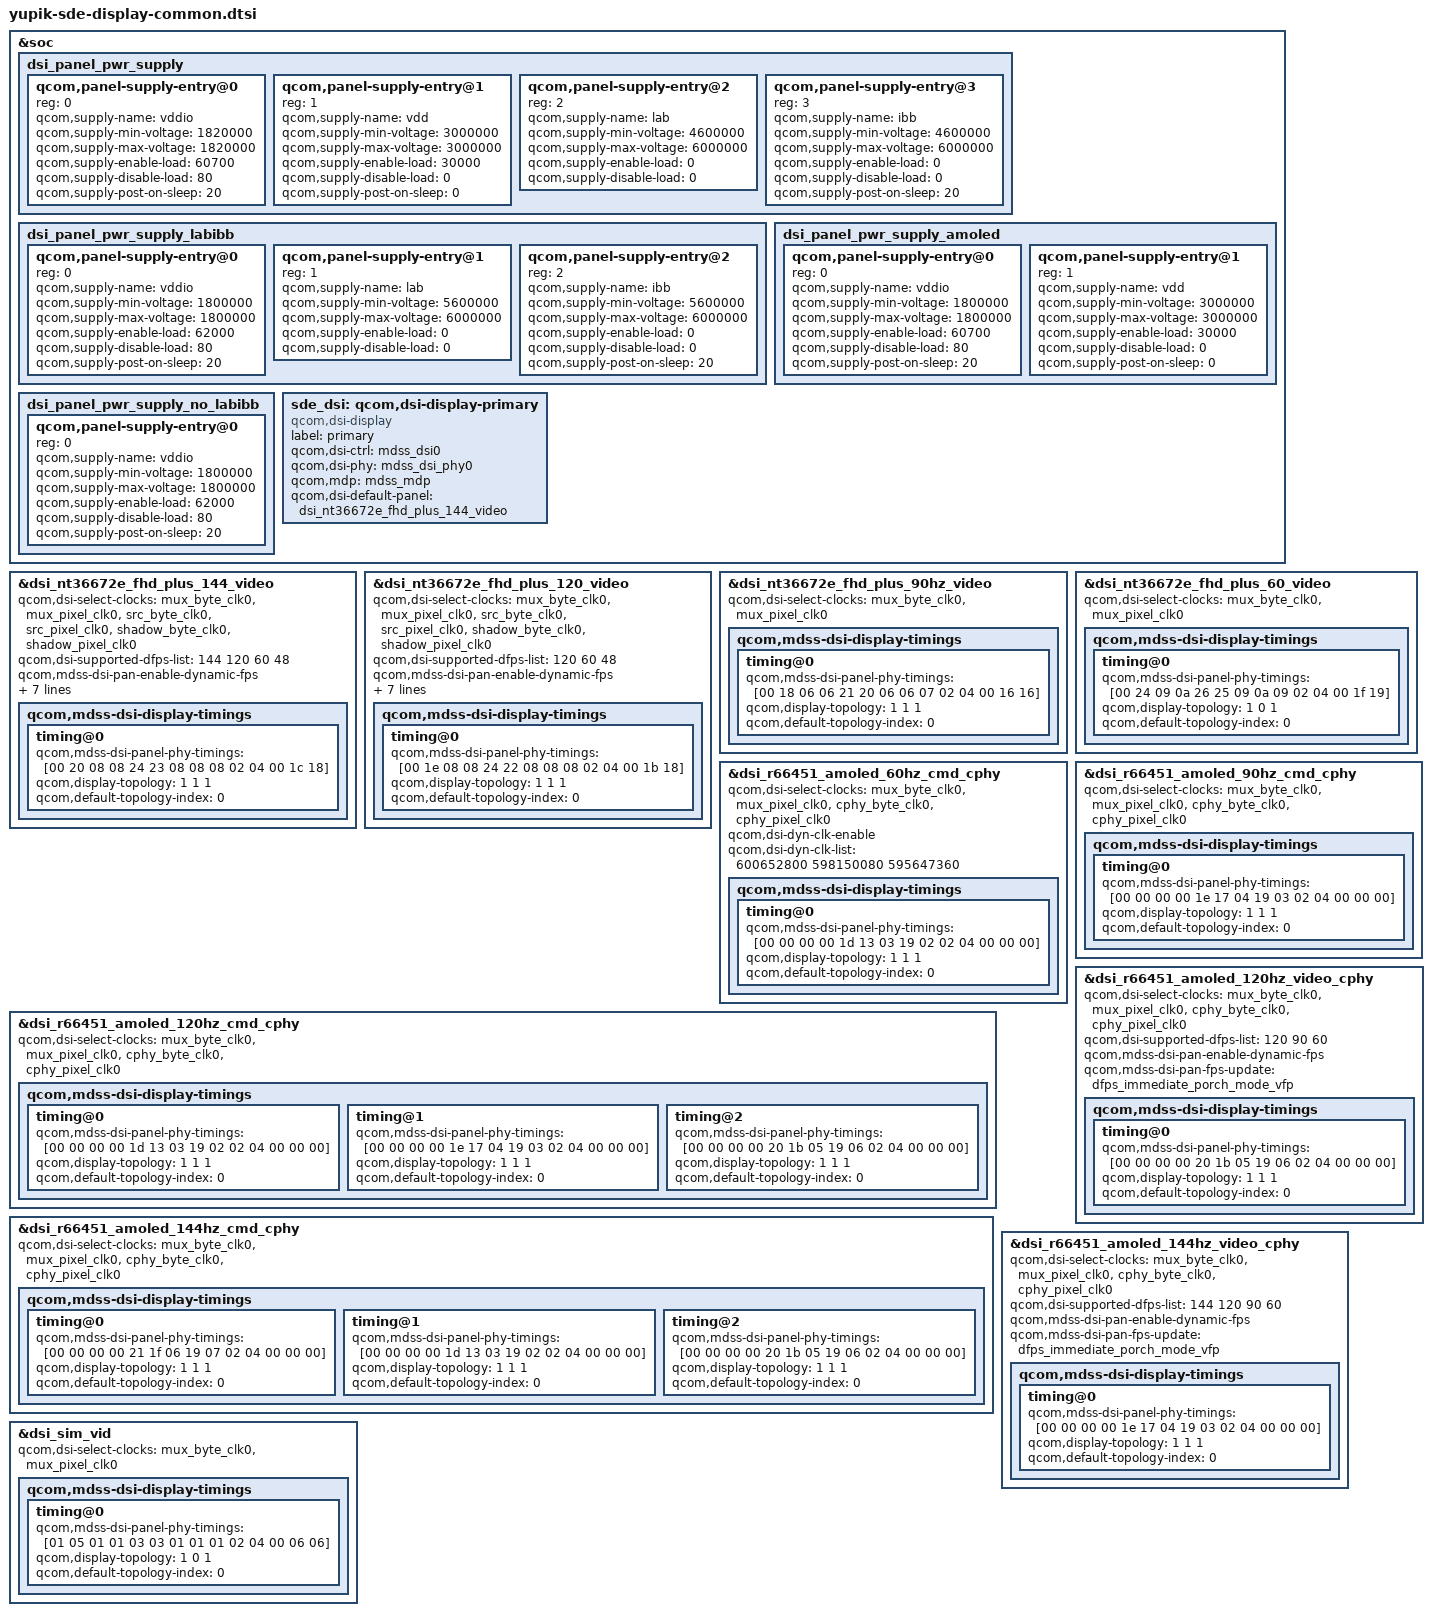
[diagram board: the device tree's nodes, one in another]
#include "dsi-panel-nt36672e-fhd-plus-144-video.dtsi"
#include "dsi-panel-nt36672e-fhd-plus-120-video.dtsi"
#include "dsi-panel-nt36672e-fhd-plus-90hz-video.dtsi"
#include "dsi-panel-nt36672e-fhd-plus-60hz-video.dtsi"
#include "dsi-panel-r66451-dsc-fhd-plus-60hz-cmd-cphy.dtsi"
#include "dsi-panel-r66451-dsc-fhd-plus-90hz-cmd-cphy.dtsi"
#include "dsi-panel-r66451-dsc-fhd-plus-120hz-cmd-cphy.dtsi"
#include "dsi-panel-r66451-dsc-fhd-plus-120hz-video-cphy.dtsi"
#include "dsi-panel-r66451-dsc-fhd-plus-144hz-cmd-cphy.dtsi"
#include "dsi-panel-r66451-dsc-fhd-plus-144hz-video-cphy.dtsi"
#include "dsi-panel-prim-sim-video.dtsi"
#include "dsi-panel-sim-video.dtsi"
#include <dt-bindings/clock/mdss-5nm-pll-clk.h>

&soc {
	dsi_panel_pwr_supply: dsi_panel_pwr_supply {
		#address-cells = <1>;
		#size-cells = <0>;

		qcom,panel-supply-entry@0 {
			reg = <0>;
			qcom,supply-name = "vddio";
			qcom,supply-min-voltage = <1820000>;
			qcom,supply-max-voltage = <1820000>;
			qcom,supply-enable-load = <60700>;
			qcom,supply-disable-load = <80>;
			qcom,supply-post-on-sleep = <20>;
		};

		qcom,panel-supply-entry@1 {
			reg = <1>;
			qcom,supply-name = "vdd";
			qcom,supply-min-voltage = <3000000>;
			qcom,supply-max-voltage = <3000000>;
			qcom,supply-enable-load = <30000>;
			qcom,supply-disable-load = <0>;
			qcom,supply-post-on-sleep = <0>;
		};

		qcom,panel-supply-entry@2 {
			reg = <2>;
			qcom,supply-name = "lab";
			qcom,supply-min-voltage = <4600000>;
			qcom,supply-max-voltage = <6000000>;
			qcom,supply-enable-load = <0>;
			qcom,supply-disable-load = <0>;
		};

		qcom,panel-supply-entry@3 {
			reg = <3>;
			qcom,supply-name = "ibb";
			qcom,supply-min-voltage = <4600000>;
			qcom,supply-max-voltage = <6000000>;
			qcom,supply-enable-load = <0>;
			qcom,supply-disable-load = <0>;
			qcom,supply-post-on-sleep = <20>;
		};
	};

	dsi_panel_pwr_supply_labibb: dsi_panel_pwr_supply_labibb {
		#address-cells = <1>;
		#size-cells = <0>;

		qcom,panel-supply-entry@0 {
			reg = <0>;
			qcom,supply-name = "vddio";
			qcom,supply-min-voltage = <1800000>;
			qcom,supply-max-voltage = <1800000>;
			qcom,supply-enable-load = <62000>;
			qcom,supply-disable-load = <80>;
			qcom,supply-post-on-sleep = <20>;
		};

		qcom,panel-supply-entry@1 {
			reg = <1>;
			qcom,supply-name = "lab";
			qcom,supply-min-voltage = <5600000>;
			qcom,supply-max-voltage = <6000000>;
			qcom,supply-enable-load = <0>;
			qcom,supply-disable-load = <0>;
		};

		qcom,panel-supply-entry@2 {
			reg = <2>;
			qcom,supply-name = "ibb";
			qcom,supply-min-voltage = <5600000>;
			qcom,supply-max-voltage = <6000000>;
			qcom,supply-enable-load = <0>;
			qcom,supply-disable-load = <0>;
			qcom,supply-post-on-sleep = <20>;
		};
	};

	dsi_panel_pwr_supply_amoled: dsi_panel_pwr_supply_amoled {
		#address-cells = <1>;
		#size-cells = <0>;

		qcom,panel-supply-entry@0 {
			reg = <0>;
			qcom,supply-name = "vddio";
			qcom,supply-min-voltage = <1800000>;
			qcom,supply-max-voltage = <1800000>;
			qcom,supply-enable-load = <60700>;
			qcom,supply-disable-load = <80>;
			qcom,supply-post-on-sleep = <20>;
		};

		qcom,panel-supply-entry@1 {
			reg = <1>;
			qcom,supply-name = "vdd";
			qcom,supply-min-voltage = <3000000>;
			qcom,supply-max-voltage = <3000000>;
			qcom,supply-enable-load = <30000>;
			qcom,supply-disable-load = <0>;
			qcom,supply-post-on-sleep = <0>;
		};
	};

	dsi_panel_pwr_supply_no_labibb: dsi_panel_pwr_supply_no_labibb {
		#address-cells = <1>;
		#size-cells = <0>;

		qcom,panel-supply-entry@0 {
			reg = <0>;
			qcom,supply-name = "vddio";
			qcom,supply-min-voltage = <1800000>;
			qcom,supply-max-voltage = <1800000>;
			qcom,supply-enable-load = <62000>;
			qcom,supply-disable-load = <80>;
			qcom,supply-post-on-sleep = <20>;
		};
	};

	sde_dsi: qcom,dsi-display-primary {
		compatible = "qcom,dsi-display";
		label = "primary";

		qcom,dsi-ctrl = <&mdss_dsi0>;
		qcom,dsi-phy = <&mdss_dsi_phy0>;

		qcom,mdp = <&mdss_mdp>;
		qcom,dsi-default-panel = <&dsi_nt36672e_fhd_plus_144_video>;
	};
};

&dsi_nt36672e_fhd_plus_144_video {
	qcom,dsi-select-clocks = "mux_byte_clk0", "mux_pixel_clk0",
				"src_byte_clk0", "src_pixel_clk0",
				"shadow_byte_clk0", "shadow_pixel_clk0";
	qcom,dsi-supported-dfps-list = <144 120 60 48>;
	qcom,mdss-dsi-pan-enable-dynamic-fps;
	qcom,mdss-dsi-pan-fps-update = "dfps_immediate_porch_mode_vfp";
	qcom,mdss-dsi-qsync-min-refresh-rate = <48>;
	qcom,dsi-dyn-clk-enable;
	qcom,dsi-dyn-clk-list =
		<953341056 946720632 950030848>;
	qcom,dsi-dyn-clk-type = "constant-fps-adjust-vfp";
	qcom,mdss-dsi-display-timings {
		timing@0 {
			qcom,mdss-dsi-panel-phy-timings = [00 20 08 08 24 23 08
				08 08 02 04 00 1c 18];
			qcom,display-topology = <1 1 1>;
			qcom,default-topology-index = <0>;
		};
	};
};

&dsi_nt36672e_fhd_plus_120_video {
	qcom,dsi-select-clocks = "mux_byte_clk0", "mux_pixel_clk0",
				"src_byte_clk0", "src_pixel_clk0",
				"shadow_byte_clk0", "shadow_pixel_clk0";
	qcom,dsi-supported-dfps-list = <120 60 48>;
	qcom,mdss-dsi-pan-enable-dynamic-fps;
	qcom,mdss-dsi-pan-fps-update = "dfps_immediate_porch_mode_vfp";
	qcom,mdss-dsi-qsync-min-refresh-rate = <48>;
	qcom,dsi-dyn-clk-enable;
	qcom,dsi-dyn-clk-list =
		<901327680 893816616 897572152>;
	qcom,dsi-dyn-clk-type = "constant-fps-adjust-vfp";
	qcom,mdss-dsi-display-timings {
		timing@0 {
			qcom,mdss-dsi-panel-phy-timings = [00 1e 08 08 24 22 08
				08 08 02 04 00 1b 18];
			qcom,display-topology = <1 1 1>;
			qcom,default-topology-index = <0>;
		};
	};
};

&dsi_nt36672e_fhd_plus_90hz_video {
	qcom,dsi-select-clocks = "mux_byte_clk0", "mux_pixel_clk0";
	qcom,mdss-dsi-display-timings {
		timing@0 {
			qcom,mdss-dsi-panel-phy-timings = [00 18 06 06 21 20 06
				06 07 02 04 00 16 16];
			qcom,display-topology = <1 1 1>;
			qcom,default-topology-index = <0>;
		};
	};
};

&dsi_nt36672e_fhd_plus_60_video {
	qcom,dsi-select-clocks = "mux_byte_clk0", "mux_pixel_clk0";
	qcom,mdss-dsi-display-timings {
		timing@0 {
			qcom,mdss-dsi-panel-phy-timings = [00 24 09 0a 26 25 09
				0a 09 02 04 00 1f 19];
			qcom,display-topology = <1 0 1>;
			qcom,default-topology-index = <0>;
		};
	};
};

&dsi_r66451_amoled_60hz_cmd_cphy {
	qcom,dsi-select-clocks = "mux_byte_clk0", "mux_pixel_clk0",
				"cphy_byte_clk0", "cphy_pixel_clk0";
	qcom,dsi-dyn-clk-enable;
	qcom,dsi-dyn-clk-list = <600652800 598150080 595647360>;
	qcom,mdss-dsi-display-timings {
		timing@0 {
			qcom,mdss-dsi-panel-phy-timings = [00 00 00 00 1d 13 03
					19 02 02 04 00 00 00];
			qcom,display-topology = <1 1 1>;
			qcom,default-topology-index = <0>;
		};
	};
};

&dsi_r66451_amoled_90hz_cmd_cphy {
	qcom,dsi-select-clocks = "mux_byte_clk0", "mux_pixel_clk0",
				"cphy_byte_clk0", "cphy_pixel_clk0";
	qcom,mdss-dsi-display-timings {
		timing@0 {
			qcom,mdss-dsi-panel-phy-timings = [00 00 00 00 1e 17 04
					19 03 02 04 00 00 00];
			qcom,display-topology = <1 1 1>;
			qcom,default-topology-index = <0>;
		};
	};
};

&dsi_r66451_amoled_120hz_cmd_cphy {
	qcom,dsi-select-clocks = "mux_byte_clk0", "mux_pixel_clk0",
				"cphy_byte_clk0", "cphy_pixel_clk0";
	qcom,mdss-dsi-display-timings {
		timing@0 {
			qcom,mdss-dsi-panel-phy-timings = [00 00 00 00 1d 13 03
					19 02 02 04 00 00 00];
			qcom,display-topology = <1 1 1>;
			qcom,default-topology-index = <0>;
		};

		timing@1 {
			qcom,mdss-dsi-panel-phy-timings = [00 00 00 00 1e 17 04
					19 03 02 04 00 00 00];
			qcom,display-topology = <1 1 1>;
			qcom,default-topology-index = <0>;
		};

		timing@2 {
			qcom,mdss-dsi-panel-phy-timings = [00 00 00 00 20 1b 05
					19 06 02 04 00 00 00];
			qcom,display-topology = <1 1 1>;
			qcom,default-topology-index = <0>;
		};
	};
};

&dsi_r66451_amoled_120hz_video_cphy {
	qcom,dsi-select-clocks = "mux_byte_clk0", "mux_pixel_clk0",
				"cphy_byte_clk0", "cphy_pixel_clk0";
	qcom,dsi-supported-dfps-list = <120 90 60>;
	qcom,mdss-dsi-pan-enable-dynamic-fps;
	qcom,mdss-dsi-pan-fps-update = "dfps_immediate_porch_mode_vfp";
	qcom,mdss-dsi-display-timings {
		timing@0 {
			qcom,mdss-dsi-panel-phy-timings = [00 00 00 00 20 1b 05
					19 06 02 04 00 00 00];
			qcom,display-topology = <1 1 1>;
			qcom,default-topology-index = <0>;
		};
	};
};

&dsi_r66451_amoled_144hz_cmd_cphy {
	qcom,dsi-select-clocks = "mux_byte_clk0", "mux_pixel_clk0",
				"cphy_byte_clk0", "cphy_pixel_clk0";
	qcom,mdss-dsi-display-timings {
		timing@0 {
			qcom,mdss-dsi-panel-phy-timings = [00 00 00 00 21 1f 06
					19 07 02 04 00 00 00];
			qcom,display-topology = <1 1 1>;
			qcom,default-topology-index = <0>;
		};

		timing@1 {
			qcom,mdss-dsi-panel-phy-timings = [00 00 00 00 1d 13 03
					19 02 02 04 00 00 00];
			qcom,display-topology = <1 1 1>;
			qcom,default-topology-index = <0>;
		};

		timing@2 {
			qcom,mdss-dsi-panel-phy-timings = [00 00 00 00 20 1b 05
					19 06 02 04 00 00 00];
			qcom,display-topology = <1 1 1>;
			qcom,default-topology-index = <0>;
		};
	};
};

&dsi_r66451_amoled_144hz_video_cphy {
	qcom,dsi-select-clocks = "mux_byte_clk0", "mux_pixel_clk0",
				"cphy_byte_clk0", "cphy_pixel_clk0";
	qcom,dsi-supported-dfps-list = <144 120 90 60>;
	qcom,mdss-dsi-pan-enable-dynamic-fps;
	qcom,mdss-dsi-pan-fps-update = "dfps_immediate_porch_mode_vfp";
	qcom,mdss-dsi-display-timings {
		timing@0 {
			qcom,mdss-dsi-panel-phy-timings = [00 00 00 00 1e 17 04
					19 03 02 04 00 00 00];
			qcom,display-topology = <1 1 1>;
			qcom,default-topology-index = <0>;
		};
	};
};

&dsi_sim_vid {
	qcom,dsi-select-clocks = "mux_byte_clk0", "mux_pixel_clk0";
	qcom,mdss-dsi-display-timings {
		timing@0 {
			qcom,mdss-dsi-panel-phy-timings = [01 05 01 01 03 03 01
				01 01 02 04 00 06 06];
			qcom,display-topology = <1 0 1>;
			qcom,default-topology-index = <0>;
		};
	};
};
